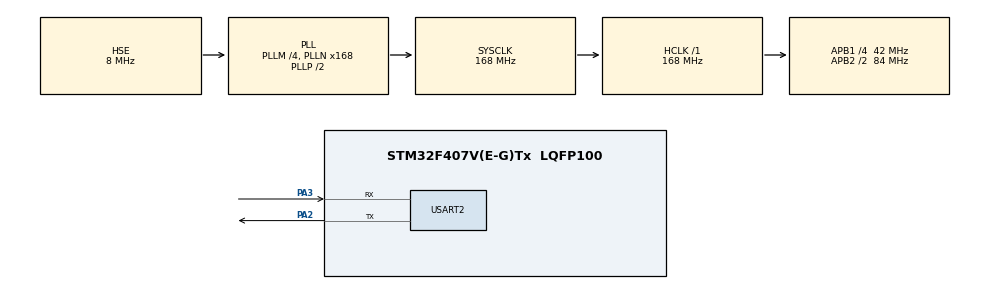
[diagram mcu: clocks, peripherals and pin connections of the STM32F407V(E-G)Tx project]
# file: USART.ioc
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Mcu.Family=STM32F4
Mcu.Name=STM32F407V(E-G)Tx
Mcu.Package=LQFP100
NVIC.PriorityGroup=NVIC_PRIORITYGROUP_4
NVIC.USART2_IRQn=true\:0\:0\:false\:false\:true\:true\:true\:true
PA13.Mode=Trace_Asynchronous_SW
PA13.Signal=SYS_JTMS-SWDIO
PA14.Mode=Trace_Asynchronous_SW
PA14.Signal=SYS_JTCK-SWCLK
PA2.Mode=Asynchronous
PA2.Signal=USART2_TX
PA3.Mode=Asynchronous
PA3.Signal=USART2_RX
PB3.Mode=Trace_Asynchronous_SW
PB3.Signal=SYS_JTDO-SWO
PH0-OSC_IN.Mode=HSE-External-Oscillator
PH0-OSC_IN.Signal=RCC_OSC_IN
PH1-OSC_OUT.Mode=HSE-External-Oscillator
PH1-OSC_OUT.Signal=RCC_OSC_OUT
ProjectManager.HeapSize=0x200
ProjectManager.StackSize=0x400
ProjectManager.TargetToolchain=STM32CubeIDE
RCC.48MHZClocksFreq_Value=84000000
RCC.AHBFreq_Value=168000000
RCC.APB1CLKDivider=RCC_HCLK_DIV4
RCC.APB1Freq_Value=42000000
RCC.APB1TimFreq_Value=84000000
RCC.APB2CLKDivider=RCC_HCLK_DIV2
RCC.APB2Freq_Value=84000000
RCC.APB2TimFreq_Value=168000000
RCC.CortexFreq_Value=168000000
RCC.HCLKFreq_Value=168000000
RCC.HSE_VALUE=8000000
RCC.HSI_VALUE=16000000
RCC.LSE_VALUE=32768
RCC.PLLM=4
RCC.PLLN=168
RCC.PLLSourceVirtual=RCC_PLLSOURCE_HSE
RCC.SYSCLKFreq_VALUE=168000000
RCC.SYSCLKSource=RCC_SYSCLKSOURCE_PLLCLK
RCC.VCOOutputFreq_Value=336000000
USART2.OverSampling=UART_OVERSAMPLING_16
USART2.VirtualMode=VM_ASYNC
board=custom

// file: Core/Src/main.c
/* USER CODE BEGIN Header */
/**
  ******************************************************************************
  * @file           : main.c
  * @brief          : Main program body
  ******************************************************************************
  * @attention
  *
  * Copyright (c) 2025 STMicroelectronics.
  * All rights reserved.
  *
  * This software is licensed under terms that can be found in the LICENSE file
  * in the root directory of this software component.
  * If no LICENSE file comes with this software, it is provided AS-IS.
  *
  ******************************************************************************
  */
/* USER CODE END Header */
#include "main.h"
#include "usart.h"
#include "gpio.h"

/* USER CODE BEGIN Includes */
#include "lwprintf.h"
/* USER CODE END Includes */

/* USER CODE BEGIN PV */
uint8_t rx_buf[32];
/* USER CODE END PV */

void SystemClock_Config(void);

/* USER CODE BEGIN 0 */
int __io_putchar(int ch){

	/**
	 * LL
	 *
	while(LL_USART_IsActiveFlag_TXE(USART2) == 0);

	LL_USART_TransmitData8(USART2, ch);
	*/
	/**
	 * HAL

	HAL_UART_Transmit(huart, pData, Size, Timeout)
	HAL_UART_Transmit_IT(huart, pData, Size)
	HAL_UART_Transmit_DMA(huart, pData, Size)
	*/
	HAL_UART_Transmit(&huart2, (uint8_t *)&ch, 1, HAL_MAX_DELAY);

	return ch;
}

int
lwprintf_out(int ch, lwprintf_t* lwp) {
    /* May use printf to output it for test */
    if (ch != '\0') {
    	HAL_UART_Transmit(&huart2, (uint8_t *)&ch, 1, HAL_MAX_DELAY);
    }
    return ch;
}

void HAL_UART2_RxCpltCallback(UART_HandleTypeDef *huart){

}
/* USER CODE END 0 */

int main(void)
{

  /* MCU Configuration--------------------------------------------------------*/

  /* Reset of all peripherals, Initializes the Flash interface and the Systick. */
  HAL_Init();

  /* Configure the system clock */
  SystemClock_Config();

  /* Initialize all configured peripherals */
  MX_GPIO_Init();
  MX_USART2_UART_Init();
  /* USER CODE BEGIN 2 */
  lwprintf_init(lwprintf_out);

//  lwprintf_printf("hola mundo desde uart\r\n");
//
//
//  lwprintf_printf("numero: %d\r\n", 10);
//
//  lwprintf_printf("volt: %.1f\r\n", 3.13);

  HAL_UART_RegisterCallback(&huart2,  HAL_UART_RX_COMPLETE_CB_ID,  HAL_UART2_RxCpltCallback);

  HAL_UART_Receive_IT(&huart2, rx_buf, 10);
  HAL_UART_Receive_IT(&huart1, rx_buf1, 10);

  HAL_UART_Transmit_IT(&huart2, rx_buf, 21);

  HAL_UART_Transmit_IT(&huart2, rx_buf, 10); //hal_error
//  HAL_UART_Receive(&huart2, (uint8_t *)buffer, 10, 1000); //hal_ok == 0

  /* USER CODE END 2 */

  /* Infinite loop */
  while (1)
  {

  }
}

void SystemClock_Config(void)
{
  RCC_OscInitTypeDef RCC_OscInitStruct = {0};
  RCC_ClkInitTypeDef RCC_ClkInitStruct = {0};

  /** Configure the main internal regulator output voltage
  */
  __HAL_RCC_PWR_CLK_ENABLE();
  __HAL_PWR_VOLTAGESCALING_CONFIG(PWR_REGULATOR_VOLTAGE_SCALE1);

  /** Initializes the RCC Oscillators according to the specified parameters
  * in the RCC_OscInitTypeDef structure.
  */
  RCC_OscInitStruct.OscillatorType = RCC_OSCILLATORTYPE_HSE;
  RCC_OscInitStruct.HSEState = RCC_HSE_ON;
  RCC_OscInitStruct.PLL.PLLState = RCC_PLL_ON;
  RCC_OscInitStruct.PLL.PLLSource = RCC_PLLSOURCE_HSE;
  RCC_OscInitStruct.PLL.PLLM = 4;
  RCC_OscInitStruct.PLL.PLLN = 168;
  RCC_OscInitStruct.PLL.PLLP = RCC_PLLP_DIV2;
  RCC_OscInitStruct.PLL.PLLQ = 4;
  if (HAL_RCC_OscConfig(&RCC_OscInitStruct) != HAL_OK)
  {
    Error_Handler();
  }

  /** Initializes the CPU, AHB and APB buses clocks
  */
  RCC_ClkInitStruct.ClockType = RCC_CLOCKTYPE_HCLK|RCC_CLOCKTYPE_SYSCLK
                              |RCC_CLOCKTYPE_PCLK1|RCC_CLOCKTYPE_PCLK2;
  RCC_ClkInitStruct.SYSCLKSource = RCC_SYSCLKSOURCE_PLLCLK;
  RCC_ClkInitStruct.AHBCLKDivider = RCC_SYSCLK_DIV1;
  RCC_ClkInitStruct.APB1CLKDivider = RCC_HCLK_DIV4;
  RCC_ClkInitStruct.APB2CLKDivider = RCC_HCLK_DIV2;

  if (HAL_RCC_ClockConfig(&RCC_ClkInitStruct, FLASH_LATENCY_5) != HAL_OK)
  {
    Error_Handler();
  }
}

/* USER CODE BEGIN 4 */
void HAL_UART_RxCpltCallback(UART_HandleTypeDef *huart)
{
	//todo: logica

	if(huart == &huart2){

	}else if(huart == &huart1){

	}
}

void HAL_UART_TxCpltCallback(UART_HandleTypeDef *huart)
{
	//todo: logica
}

/* USER CODE END 4 */

void Error_Handler(void)
{
  __disable_irq();
  while (1)
  {
  }
}
